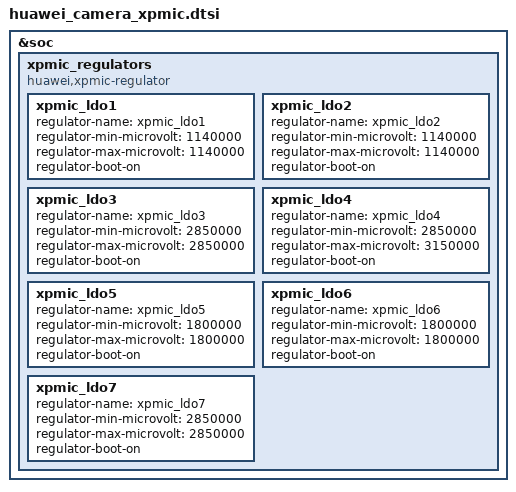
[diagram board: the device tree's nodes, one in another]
&soc {
	status = "ok";

	xpmic_regulators: xpmic_regulators {
		compatible = "huawei,xpmic-regulator";

		xpmic_ldo1: xpmic_ldo1 {
			regulator-name = "xpmic_ldo1";
			regulator-min-microvolt = <1140000>;
			regulator-max-microvolt = <1140000>;
			regulator-boot-on;
		};
		xpmic_ldo2: xpmic_ldo2 {
			regulator-name = "xpmic_ldo2";
			regulator-min-microvolt = <1140000>;
			regulator-max-microvolt = <1140000>;
			regulator-boot-on;
		};
		xpmic_ldo3: xpmic_ldo3 {
			regulator-name = "xpmic_ldo3";
			regulator-min-microvolt = <2850000>;
			regulator-max-microvolt = <2850000>;
			regulator-boot-on;
		};
		xpmic_ldo4: xpmic_ldo4 {
			regulator-name = "xpmic_ldo4";
			regulator-min-microvolt = <2850000>;
			regulator-max-microvolt = <3150000>;
			regulator-boot-on;
		};
		xpmic_ldo5: xpmic_ldo5 {
			regulator-name = "xpmic_ldo5";
			regulator-min-microvolt = <1800000>;
			regulator-max-microvolt = <1800000>;
			regulator-boot-on;
		};
		xpmic_ldo6: xpmic_ldo6 {
			regulator-name = "xpmic_ldo6";
			regulator-min-microvolt = <1800000>;
			regulator-max-microvolt = <1800000>;
			regulator-boot-on;
		};
		xpmic_ldo7: xpmic_ldo7 {
			regulator-name = "xpmic_ldo7";
			regulator-min-microvolt = <2850000>;
			regulator-max-microvolt = <2850000>;
			regulator-boot-on;
		};
	};
};
